# ESP32-S31 register map
Vendor: ESPRESSIF SYSTEMS (SHANGHAI) CO., LTD.; Series: ESP32 S-Series; File version: 1
CPU: RV32IMAFC r0p0, little endian, no MPU, FPU, 0 interrupt priority bits
Address unit: 32 bits
Registers are 32-bit, read-write, reset 0x0 unless marked. A register's access mark holds for its fields unless they carry their own. Offsets are from the block's base; [hi:lo] are bit positions; {n}, {i} and the like mark numbered series; <NAME> marks a mode.

## I2C0 — I2C (Inter-Integrated Circuit) Controller 0
Base 0x20385000
Same registers: I2C1 0x20386000, LP_I2C 0x20811000
0x00 SCL_LOW_PERIOD — Configures the low level width of the SCL Clock
  [8:0] SCL_LOW_PERIOD — Configures the low level width of the SCL Clock in Master mode. \\ Measurement unit: I2C_SCLK \\
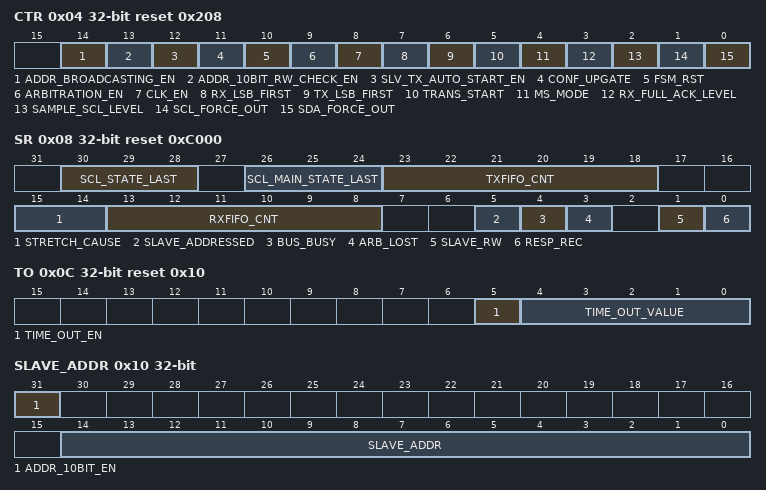
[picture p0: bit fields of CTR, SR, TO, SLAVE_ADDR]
0x04 CTR access per field reset 0x208 — Transmission setting register
  [14] ADDR_BROADCASTING_EN rw — Configures whether to support the 7-bit general call function.\\ 0: Not support \\ 1: Support \\
  [13] ADDR_10BIT_RW_CHECK_EN rw — Configures whether to check if the 13/\overline W$ bit of 10-bit addressing consists with I2C protocol.\\ 0: Not check\\ 1: Check
  [12] SLV_TX_AUTO_START_EN rw — Configures whether to enable slave to send data automatically\\ 0: Disable\\ 1: Enable \\
  [11] CONF_UPGATE wo — Configures the bit for synchronization.\\ 0: No effect \\ 1: Synchronize
  [10] FSM_RST wo — Configures whether to reset the SCL_FSM.\\ 0: No effect \\ 1: Reset
  [9] ARBITRATION_EN rw — Configures whether to enable I2C bus arbitration detection.\\ 0: No effect \\ 1: Enable \\
  [8] CLK_EN rw — Configures whether to gate clock signal for registers.\\ 0: Support clock only when registers are read or written to by software \\ 1: Force clock on for registers \\
  [7] RX_LSB_FIRST rw — Configures whether or not to control the storage order for received data.\\ 0: Receive data from the most significant bit \\ 1: Receive data from the least significant bit \\
  [6] TX_LSB_FIRST rw — Configures whether or not to control the sending order for data needing to be sent.\\ 0: Send data from the most significant bit \\ 1: Send data from the least significant bit \\
  [5] TRANS_START wo — Configures whether the slave starts sending the data in TX FIFO.\\ 0: No effect \\ 1: Start
  [4] MS_MODE rw — Configures the module as an I2C Master or Slave.\\ 0: Slave \\ 1: Master \\
  [3] RX_FULL_ACK_LEVEL rw — Configures the ACK value that needs to be sent by master when rx_fifo_cnt has reached the threshold.\\
  [2] SAMPLE_SCL_LEVEL rw — Configures the sample mode for SDA.\\ 0: Sample SDA data on the SCL high level \\ 1: Sample SDA data on the SCL low level \\
  [1] SCL_FORCE_OUT rw — Configures the SCL output mode.\\ 0: Open drain output \\ 1: Direct output \\
  [0] SDA_FORCE_OUT rw — Configures the SDA output mode.\\ 0: Open drain output \\ 1: Direct output \\
0x08 SR ro reset 0xC000 — I2C working status register
  [30:28] SCL_STATE_LAST — Represents the states of the state machine used to produce SCL.\\ 0: Idle\\ 1: Start\\ 2: Negative edge\\ 3: Low\\ 4: Positive edge\\ 5: High\\ 6: Stop \\
  [26:24] SCL_MAIN_STATE_LAST — Represents the states of the I2C module state machine.\\ 0: Idle\\ 1: Address shift\\ 2: ACK address\\ 3: Rx data\\ 4: Tx data\\ 5: Send ACK\\ 6: Wait ACK \\
  [23:18] TXFIFO_CNT — Represents the number of data bytes to be sent.
  [15:14] STRETCH_CAUSE — Represents the cause of SCL clocking stretching in Slave mode.\\ 0: Stretching SCL low when the master starts to read data.\\ 1: Stretching SCL low when I2C TX FIFO is empty in Slave mode.\\ 2: Stretching SCL low when I2C RX FIFO is full in Slave mode.
  [13:8] RXFIFO_CNT — Represents the number of data bytes received in RAM.
  [5] SLAVE_ADDRESSED — Represents whether the address sent by the master is equal to the address of the slave.\\ Valid only when the module is configured as an I2C Slave.\\ 0: Not equal\\ 1: Equal\\
  [4] BUS_BUSY — Represents the I2C bus state.\\ 0: The I2C bus is in idle state\\ 1: The I2C bus is busy transferring data\\
  [3] ARB_LOST — Represents whether the I2C controller loses control of SCL line.\\ 0: No arbitration lost\\ 1: Arbitration lost\\
  [1] SLAVE_RW — Represents the transfer direction in Slave mode.\\ 0: Master writes to slave\\ 1: Master reads from slave\\
  [0] RESP_REC — Represents the received ACK value in Master mode or Slave mode.\\ 0: ACK\\ 1: NACK\\
0x0C TO reset 0x10 — Timeout control register for receiving data
  [5] TIME_OUT_EN — Configures whether to enable timeout control.\\ 0: No effect \\ 1: Enable \\
  [4:0] TIME_OUT_VALUE — Configures the timeout threshold period for SCL stucking at high or low level. The actual period is 2\^{}(reg_time_out_value).\\ Measurement unit: I2C_SCLK \\
0x10 SLAVE_ADDR — Local slave address setting register
  [31] ADDR_10BIT_EN — Configures whether to enable the slave 10-bit addressing mode in Master mode.\\ 0: No effect \\ 1: Enable \\
  [14:0] SLAVE_ADDR — Configures the slave address of the I2C slave.\\
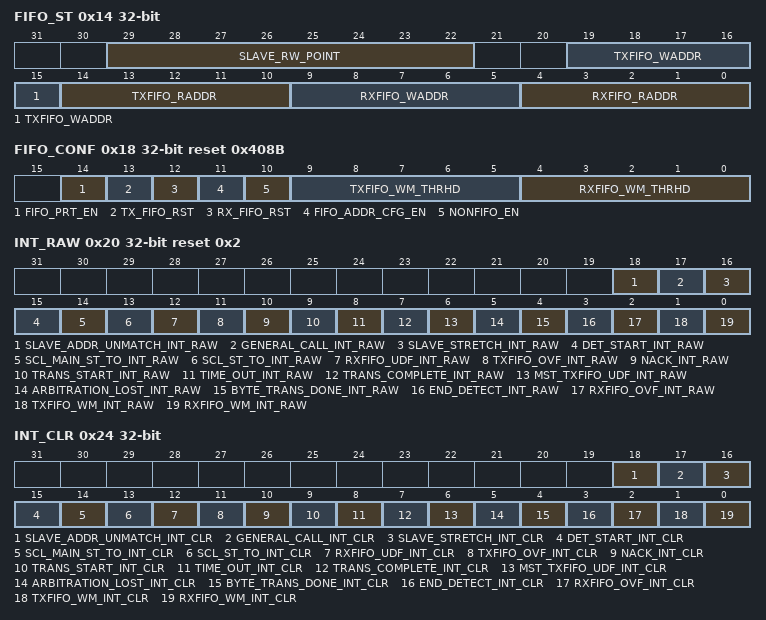
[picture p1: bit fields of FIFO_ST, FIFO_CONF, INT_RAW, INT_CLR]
0x14 FIFO_ST ro — FIFO status register
  [29:22] SLAVE_RW_POINT — Represents the offset address in the I2C Slave RAM addressed by I2C Master when in I2C Slave mode.
  [19:15] TXFIFO_WADDR — Represents the offset address of APB bus writing to TX FIFO.
  [14:10] TXFIFO_RADDR — Represents the offset address of I2C module reading from TX FIFO.
  [9:5] RXFIFO_WADDR — Represents the offset address of i2c module receiving data and writing to RX FIFO.
  [4:0] RXFIFO_RADDR — Represents the offset address of the APB reading from RX FIFO.
0x18 FIFO_CONF reset 0x408B — FIFO configuration register
  [14] FIFO_PRT_EN — Configures whether to enable FIFO pointer in non-FIFO access mode. This bit controls the valid bits and the TX/RX FIFO overflow, underflow, full and empty interrupts.\\ 0: No effect \\ 1: Enable \\
  [13] TX_FIFO_RST — Configures whether or not to reset TX FIFO.\\ 0: No effect \\ 1: Reset
  [12] RX_FIFO_RST — Configures whether or not to reset RX FIFO.\\ 0: No effect \\ 1: Reset
  [11] FIFO_ADDR_CFG_EN — Configures the slave to enable dual address mode. When this mode is enabled, the byte received after the I2C address byte represents the offset address in the I2C Slave RAM. \\ 0: Disable\\ 1: Enable \\
  [10] NONFIFO_EN — Configures whether to enable APB non-FIFO access.
  [9:5] TXFIFO_WM_THRHD — Configures the watermark threshold of TX FIFO in non-FIFO access mode. When I2C_FIFO_PRT_EN is 1 and TC FIFO counter is bigger than I2C_TXFIFO_WM_THRHD[4:0], the I2C_TXFIFO_WM_INT_RAW bit will be valid.
  [4:0] RXFIFO_WM_THRHD — Configures the watermark threshold of RX FIFO in non-FIFO access mode. When I2C_FIFO_PRT_EN is 1 and RX FIFO counter is bigger than I2C_RXFIFO_WM_THRHD[4:0], the I2C_RXFIFO_WM_INT_RAW bit will be valid.
0x1C DATA ro — Rx FIFO read data
  [7:0] FIFO_RDATA — Represents the value of RXFIFO read data.
0x20 INT_RAW ro reset 0x2 — Raw interrupt status register
  [18] SLAVE_ADDR_UNMATCH_INT_RAW — The raw interrupt status of I2C_SLAVE_ADDR_UNMATCH_INT.
  [17] GENERAL_CALL_INT_RAW — The raw interrupt status of I2C_GENERAL_CALL_INT.
  [16] SLAVE_STRETCH_INT_RAW — The raw interrupt status of I2C_SLAVE_STRETCH_INT.
  [15] DET_START_INT_RAW — The raw interrupt status of I2C_DET_START_INT.
  [14] SCL_MAIN_ST_TO_INT_RAW — The raw interrupt status of I2C_SCL_MAIN_ST_TO_INT.
  [13] SCL_ST_TO_INT_RAW — The raw interrupt status of I2C_SCL_ST_TO_INT.
  [12] RXFIFO_UDF_INT_RAW — The raw interrupt status of I2C_RXFIFO_UDF_INT.
  [11] TXFIFO_OVF_INT_RAW — The raw interrupt status of I2C_TXFIFO_OVF_INT.
  [10] NACK_INT_RAW — The raw interrupt status of I2C_NACK_INT.
  [9] TRANS_START_INT_RAW — The raw interrupt status of I2C_TRANS_START_INT.
  [8] TIME_OUT_INT_RAW — The raw interrupt status of I2C_TIME_OUT_INT.
  [7] TRANS_COMPLETE_INT_RAW — The raw interrupt status of the I2C_TRANS_COMPLETE_INT.
  [6] MST_TXFIFO_UDF_INT_RAW — The raw interrupt status of I2C_MST_TXFIFO_UDF_INT.
  [5] ARBITRATION_LOST_INT_RAW — The raw interrupt status of I2C_ARBITRATION_LOST_INT.
  [4] BYTE_TRANS_DONE_INT_RAW — The raw interrupt status of I2C_BYTE_TRANS_DONE_INT.
  [3] END_DETECT_INT_RAW — The raw interrupt status of I2C_END_DETECT_INT.
  [2] RXFIFO_OVF_INT_RAW — The raw interrupt status of I2C_RXFIFO_OVF_INT.
  [1] TXFIFO_WM_INT_RAW — The raw interrupt status of I2C_TXFIFO_WM_INT.
  [0] RXFIFO_WM_INT_RAW — The raw interrupt status of I2C_RXFIFO_WM_INT.
0x24 INT_CLR wo — Interrupt clear register
  [18] SLAVE_ADDR_UNMATCH_INT_CLR — Write 1 to clear I2C_SLAVE_ADDR_UNMATCH_INT.
  [17] GENERAL_CALL_INT_CLR — Write 1 to clear I2C_GENERAL_CALL_INT.
  [16] SLAVE_STRETCH_INT_CLR — Write 1 to clear I2C_SLAVE_STRETCH_INT.
  [15] DET_START_INT_CLR — Write 1 to clear I2C_DET_START_INT.
  [14] SCL_MAIN_ST_TO_INT_CLR — Write 1 to clear I2C_SCL_MAIN_ST_TO_INT.
  [13] SCL_ST_TO_INT_CLR — Write 1 to clear I2C_SCL_ST_TO_INT.
  [12] RXFIFO_UDF_INT_CLR — Write 1 to clear I2C_RXFIFO_UDF_INT.
  [11] TXFIFO_OVF_INT_CLR — Write 1 to clear I2C_TXFIFO_OVF_INT.
  [10] NACK_INT_CLR — Write 1 to clear I2C_NACK_INT.
  [9] TRANS_START_INT_CLR — Write 1 to clear I2C_TRANS_START_INT.
  [8] TIME_OUT_INT_CLR — Write 1 to clear I2C_TIME_OUT_INT.
  [7] TRANS_COMPLETE_INT_CLR — Write 1 to clear I2C_TRANS_COMPLETE_INT.
  [6] MST_TXFIFO_UDF_INT_CLR — Write 1 to clear I2C_MST_TXFIFO_UDF_INT.
  [5] ARBITRATION_LOST_INT_CLR — Write 1 to clear I2C_ARBITRATION_LOST_INT.
  [4] BYTE_TRANS_DONE_INT_CLR — Write 1 to clear I2C_BYTE_TRANS_DONE_INT.
  [3] END_DETECT_INT_CLR — Write 1 to clear I2C_END_DETECT_INT.
  [2] RXFIFO_OVF_INT_CLR — Write 1 to clear I2C_RXFIFO_OVF_INT.
  [1] TXFIFO_WM_INT_CLR — Write 1 to clear I2C_TXFIFO_WM_INT.
  [0] RXFIFO_WM_INT_CLR — Write 1 to clear I2C_RXFIFO_WM_INT.
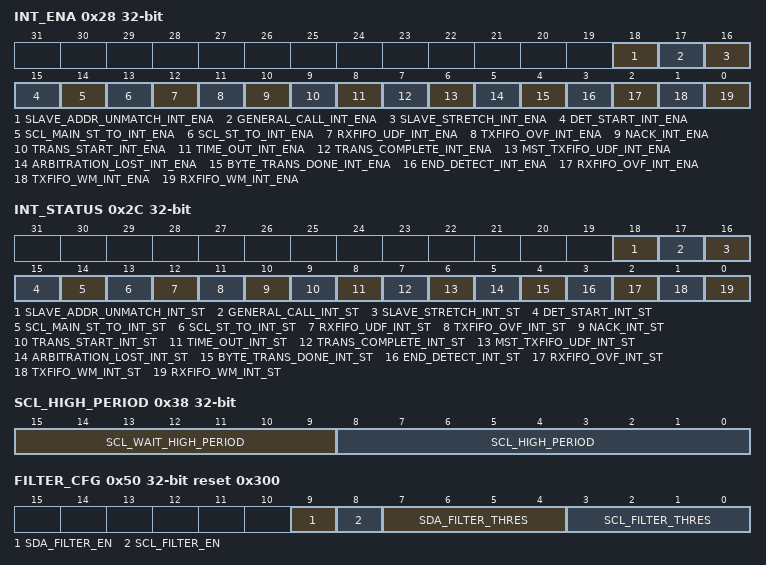
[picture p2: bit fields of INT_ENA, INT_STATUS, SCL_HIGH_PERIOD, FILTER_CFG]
0x28 INT_ENA — Interrupt enable register
  [18] SLAVE_ADDR_UNMATCH_INT_ENA — Write 1 to enable I2C_SLAVE_ADDR_UNMATCH_INT.
  [17] GENERAL_CALL_INT_ENA — Write 1 to enable I2C_GENERAL_CALL_INT.
  [16] SLAVE_STRETCH_INT_ENA — Write 1 to enable I2C_SLAVE_STRETCH_INT.
  [15] DET_START_INT_ENA — Write 1 to enable I2C_DET_START_INT.
  [14] SCL_MAIN_ST_TO_INT_ENA — Write 1 to enable I2C_SCL_MAIN_ST_TO_INT.
  [13] SCL_ST_TO_INT_ENA — Write 1 to enable I2C_SCL_ST_TO_INT.
  [12] RXFIFO_UDF_INT_ENA — Write 1 to enable I2C_RXFIFO_UDF_INT.
  [11] TXFIFO_OVF_INT_ENA — Write 1 to enable I2C_TXFIFO_OVF_INT.
  [10] NACK_INT_ENA — Write 1 to enable I2C_NACK_INT.
  [9] TRANS_START_INT_ENA — Write 1 to enable I2C_TRANS_START_INT.
  [8] TIME_OUT_INT_ENA — Write 1 to enable I2C_TIME_OUT_INT.
  [7] TRANS_COMPLETE_INT_ENA — Write 1 to enable I2C_TRANS_COMPLETE_INT.
  [6] MST_TXFIFO_UDF_INT_ENA — Write 1 to enable I2C_MST_TXFIFO_UDF_INT.
  [5] ARBITRATION_LOST_INT_ENA — Write 1 to enable I2C_ARBITRATION_LOST_INT.
  [4] BYTE_TRANS_DONE_INT_ENA — Write 1 to enable I2C_BYTE_TRANS_DONE_INT.
  [3] END_DETECT_INT_ENA — Write 1 to enable I2C_END_DETECT_INT.
  [2] RXFIFO_OVF_INT_ENA — Write 1 to enable I2C_RXFIFO_OVF_INT.
  [1] TXFIFO_WM_INT_ENA — Write 1 to enable I2C_TXFIFO_WM_INT.
  [0] RXFIFO_WM_INT_ENA — Write 1 to enable I2C_RXFIFO_WM_INT.
0x2C INT_STATUS ro — Status register of captured I2C communication events
  [18] SLAVE_ADDR_UNMATCH_INT_ST — The masked interrupt status of I2C_SLAVE_ADDR_UNMATCH_INT.
  [17] GENERAL_CALL_INT_ST — The masked interrupt status of I2C_GENERAL_CALL_INT.
  [16] SLAVE_STRETCH_INT_ST — The masked interrupt status of I2C_SLAVE_STRETCH_INT.
  [15] DET_START_INT_ST — The masked interrupt status of I2C_DET_START_INT.
  [14] SCL_MAIN_ST_TO_INT_ST — The masked interrupt status of I2C_SCL_MAIN_ST_TO_INT.
  [13] SCL_ST_TO_INT_ST — The masked interrupt status of I2C_SCL_ST_TO_INT.
  [12] RXFIFO_UDF_INT_ST — The masked interrupt status of I2C_RXFIFO_UDF_INT.
  [11] TXFIFO_OVF_INT_ST — The masked interrupt status of I2C_TXFIFO_OVF_INT.
  [10] NACK_INT_ST — The masked interrupt status of I2C_NACK_INT.
  [9] TRANS_START_INT_ST — The masked interrupt status of I2C_TRANS_START_INT.
  [8] TIME_OUT_INT_ST — The masked interrupt status of I2C_TIME_OUT_INT.
  [7] TRANS_COMPLETE_INT_ST — The masked interrupt status of I2C_TRANS_COMPLETE_INT.
  [6] MST_TXFIFO_UDF_INT_ST — The masked interrupt status of I2C_MST_TXFIFO_UDF_INT.
  [5] ARBITRATION_LOST_INT_ST — The masked interrupt status of I2C_ARBITRATION_LOST_INT.
  [4] BYTE_TRANS_DONE_INT_ST — The masked interrupt status of I2C_BYTE_TRANS_DONE_INT.
  [3] END_DETECT_INT_ST — The masked interrupt status of I2C_END_DETECT_INT.
  [2] RXFIFO_OVF_INT_ST — The masked interrupt status of I2C_RXFIFO_OVF_INT.
  [1] TXFIFO_WM_INT_ST — The masked interrupt status of I2C_TXFIFO_WM_INT.
  [0] RXFIFO_WM_INT_ST — The masked interrupt status of I2C_RXFIFO_WM_INT.
0x30 SDA_HOLD — Configures the hold time after a negative SCL edge
  [8:0] TIME — Configures the time to hold the data after the falling edge of SCL.\\ Measurement unit: I2C_SCLK \\
0x34 SDA_SAMPLE — Configures the sample time after a positive SCL edge
  [8:0] TIME — Configures the time for sampling SDA.\\ Measurement unit: I2C_SCLK \\
0x38 SCL_HIGH_PERIOD — Configures the high level width of SCL
  [15:9] SCL_WAIT_HIGH_PERIOD — Configures the SCL_FSM's waiting period for SCL high level in Master mode.\\ Measurement unit: I2C_SCLK \\
  [8:0] SCL_HIGH_PERIOD — Configures for how long SCL remains high in Master mode.\\ Measurement unit: I2C_SCLK \\
0x40 SCL_START_HOLD reset 0x8 — Configures the delay between the SDA and SCL negative edge for a start condition
  [8:0] TIME — Configures the time between the falling edge of SDA and the falling edge of SCL for a START condition.\\ Measurement unit: I2C_SCLK \\
0x44 SCL_RSTART_SETUP reset 0x8 — Configures the delay between the positive edge of SCL and the negative edge of SDA
  [8:0] TIME — Configures the time between the positive edge of SCL and the negative edge of SDA for a RESTART condition.\\ Measurement unit: I2C_SCLK \\
0x48 SCL_STOP_HOLD reset 0x8 — Configures the delay after the SCL clock edge for a stop condition
  [8:0] TIME — Configures the delay after the STOP condition.\\ Measurement unit: I2C_SCLK \\
0x4C SCL_STOP_SETUP reset 0x8 — Configures the delay between the SDA and SCL rising edge for a stop condition. Measurement unit: I2C_SCLK
  [8:0] TIME — Configures the time between the rising edge of SCL and the rising edge of SDA.\\ Measurement unit: I2C_SCLK \\
0x50 FILTER_CFG reset 0x300 — SCL and SDA filter configuration register
  [9] SDA_FILTER_EN — Configures whether to enable the filter function for SDA. \\ 0: No effect \\ 1: Enable \\
  [8] SCL_FILTER_EN — Configures whether to enable the filter function for SCL. \\ 0: No effect \\ 1: Enable \\
  [7:4] SDA_FILTER_THRES — Configures the threshold pulse width to be filtered on SDA. When a pulse on the SDA input has smaller width than this register value, the I2C controller will ignore that pulse. Measurement unit: I2C_SCLK \\
  [3:0] SCL_FILTER_THRES — Configures the threshold pulse width to be filtered on SCL. When a pulse on the SCL input has smaller width than this register value, the I2C controller will ignore that pulse. Measurement unit: I2C_SCLK \\
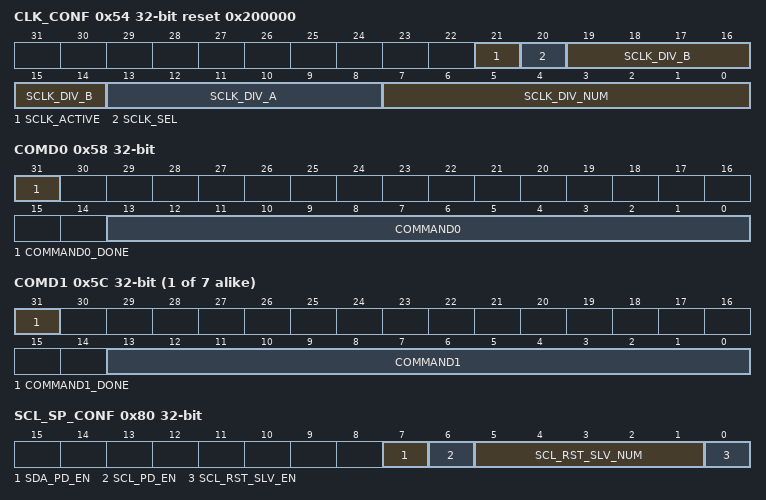
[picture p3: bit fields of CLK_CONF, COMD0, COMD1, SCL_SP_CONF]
0x54 CLK_CONF reset 0x200000 — I2C CLK configuration register
  [21] SCLK_ACTIVE — The clock switch for i2c module
  [20] SCLK_SEL — The clock selection for i2c module:0-XTAL,1-CLK_8MHz.
  [19:14] SCLK_DIV_B — the denominator of the fractional part of the fractional divisor for i2c module
  [13:8] SCLK_DIV_A — the numerator of the fractional part of the fractional divisor for i2c module
  [7:0] SCLK_DIV_NUM — the integral part of the fractional divisor for i2c module
0x58 COMD0 — I2C command register 0
  [31] COMMAND0_DONE — Represents whether command 0 is done in I2C Master mode.\\ 0: Not done \\ 1: Done \\
  [13:0] COMMAND0 — Configures command 0. \\ It consists of three parts:\\ op_code is the command\\ 0: RSTART\\ 1: WRITE\\ 2: READ\\ 3: STOP\\ 4: END.\\ Byte_num represents the number of bytes that need to be sent or received.\\ ack_check_en, ack_exp, and ack are used to control the ACK bit. See I2C cmd structure <a href=fig:i2c-cmd-structure">link</a> for more information. \\"
{0x58+4i} COMD{i} (i=1..7) — I2C command register {i}
  [31] COMMAND{i}_DONE — Represents whether command {i} is done in I2C Master mode.\\ 0: Not done \\ 1: Done \\
  [13:0] COMMAND{i} — Configures command {i}. See details in I2C_COMD0_REG [13:0].
0x78 SCL_ST_TIME_OUT reset 0x10 — SCL status timeout register
  [4:0] SCL_ST_TO_I2C — Configures the threshold value of SCL_FSM state unchanged period. It should be no more than 23, more than 1.\\ \[ ext{Threshold} = 2^{ ext{I2C_SCL_ST_TO_I2C} - 1} \] Measurement unit: I2C_SCLK \\
0x7C SCL_MAIN_ST_TIME_OUT reset 0x10 — SCL main status timeout register
  [4:0] SCL_MAIN_ST_TO_I2C — Configures the threshold value of SCL_MAIN_FSM state unchanged period. It should be no more than 23.\\ Measurement unit: I2C_SCLK \\
0x80 SCL_SP_CONF — Power configuration register
  [7] SDA_PD_EN — Configures whether or not to power down the I2C output SDA line. \\ 0: Not power down\\ 1: Power down\\ Valid only when I2C_SDA_FORCE_OUT is 1.
  [6] SCL_PD_EN — Configures whether or not to power down the I2C output SCL line. \\ 0: Not power down\\ 1: Power down\\ Valid only when I2C_SCL_FORCE_OUT is 1.
  [5:1] SCL_RST_SLV_NUM — Configure the pulses of SCL generated in I2C Master mode. \\ Valid when I2C_SCL_RST_SLV_EN is 1.\\ Measurement unit: I2C_SCLK \\
  [0] SCL_RST_SLV_EN — Configures whether or not to send out SCL pulses when I2C master is IDLE. The number of pulses equals to I2C_SCL_RST_SLV_NUM[4:0].
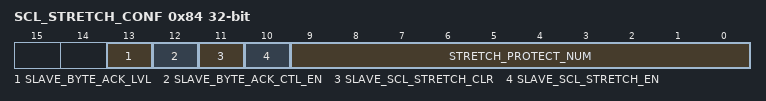
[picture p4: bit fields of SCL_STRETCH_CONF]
0x84 SCL_STRETCH_CONF access per field — SCL stretch setting register of I2C slave
  [13] SLAVE_BYTE_ACK_LVL rw — Configures the ACK level when slave controlling ACK level function enables.\\ 0: Low level\\ 1: High level \\
  [12] SLAVE_BYTE_ACK_CTL_EN rw — Configures whether to enable the function for slave to control ACK level.\\ 0: Disable \\ 1: Enable \\
  [11] SLAVE_SCL_STRETCH_CLR wo — Configures whether or not to clear the I2C slave SCL stretch function.\\ 0: No effect \\ 1: Clear\\
  [10] SLAVE_SCL_STRETCH_EN rw — Configures whether to enable slave SCL stretch function. The SCL output line will be stretched low when I2C_SLAVE_SCL_STRETCH_EN is 1 and stretch event happens. The stretch cause can be seen in I2C_STRETCH_CAUSE.\\ 0: Disable \\ 1: Enable \\
  [9:0] STRETCH_PROTECT_NUM rw — Configures the time period to release the SCL line from stretching to avoid timing violation. Usually it should be larger than the SDA setup time.\\ Measurement unit: I2C_SCLK \\
0xF8 DATE reset 0x2505060 — Version control register
  [31:0] DATE — Version control register.
0x100 TXFIFO_START_ADDR ro — I2C TXFIFO base address register
  [31:0] TXFIFO_START_ADDR — Represents the I2C TX FIFO first address.
0x180 RXFIFO_START_ADDR ro — I2C RXFIFO base address register
  [31:0] RXFIFO_START_ADDR — Represents the I2C RX FIFO first address.
